# ADuCM322i register map
Vendor: Analog Devices Inc.; Series: ARMCM3; File version: 1.0
CPU: CM3 r2p1, little endian, no MPU, no FPU, 3 interrupt priority bits
Registers are 16-bit, read-write, no defined reset value unless marked. A register's access mark holds for its fields unless they carry their own. Offsets are from the block's base; [hi:lo] are bit positions; {n}, {i} and the like mark numbered series.

## GPIO2 — General Purpose Input Output 2
Base 0x40020080
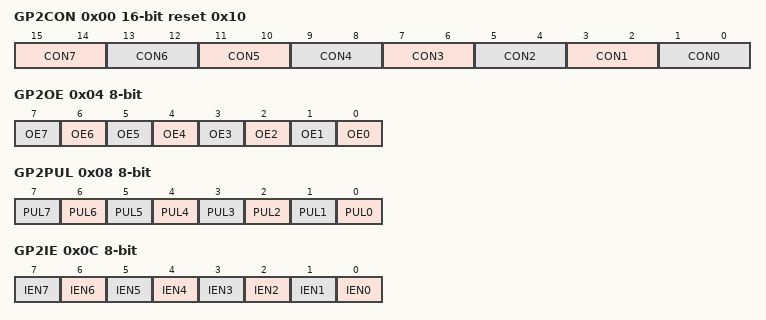
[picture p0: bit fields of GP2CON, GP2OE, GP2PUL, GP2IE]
0x00 GP2CON reset 0x10 (reset mask 0x0) — GPIO Port 2 configuration
  [15:14] CON7 — p2.7 configuration bits
    0=GPIOIRQ8; 3=PLAO11
  [13:12] CON6 — p2.6 configuration bits
    0=GPIOIRQ7; 3=PLAO10
  [11:10] CON5 — p2.5 configuration bits
    0=GPIOIRQ6; 2=PWM7; 3=PLAO9
  [9:8] CON4 — p2.4 configuration bits
    0=GIPOIRQ5 (GPIO/IRQ5); 1=ADCCONVSTIN (ADC_CONVST input); 2=PWM6; 3=PLAO8
  [7:6] CON3 — p2.3 configuration bits
    0=GPIOBM
  [5:4] CON2 — p2.2 configuration bits
    0=GPIOIRQ4; 2=EXTCLKOUT (External Clock output); 3=PLAI10
  [3:2] CON1 — p2.1 configuration bits
    0=GPIOIRQ3; 1=PWMSYNC; 3=PLAI9
  [1:0] CON0 — p2.0 configuration bits
    0=GPIOIRQ2; 1=PWMTRIP; 2=PLACLK2; 3=PLAI8
0x04 GP2OE 8-bit — GPIO Port 2 output enable
  [all] fields
    0=DIS; 1=EN
  [n] OE{n} (n=0..7) — Pin Output Drive enable
0x08 GP2PUL 8-bit — GPIO Port 2 pullup enable
  [all] fields
    0=DIS; 1=EN
  [n] PUL{n} (n=0..7) — Pin Pull up enable
0x0C GP2IE 8-bit — GPIO Port 2 input path enable
  [all] fields
    0=DIS; 1=EN
  [n] IEN{n} (n=0..7) — Input path enable
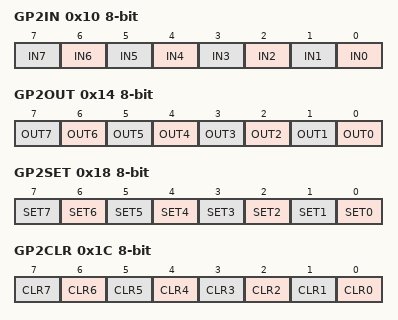
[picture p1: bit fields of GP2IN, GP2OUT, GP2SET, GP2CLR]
0x10 GP2IN 8-bit ro — GPIO Port 2 registered data input
  [all] fields
    0=LOW; 1=HIGH
  [n] IN{n} (n=0..7) — Registered data input
0x14 GP2OUT 8-bit — GPIO Port 2 data output
  [all] fields
    0=LOW; 1=HIGH
  [n] OUT{n} (n=0..7) — Data out
0x18 GP2SET 8-bit wo — GPIO Port 2 data out set
  [all] fields
    1=SET
  [n] SET{n} (n=0..7) — Set the output HIGH for the pin
0x1C GP2CLR 8-bit wo — GPIO Port 2 data out clear
  [all] fields
    1=CLR
  [n] CLR{n} (n=0..7) — Set the output low for the port pin
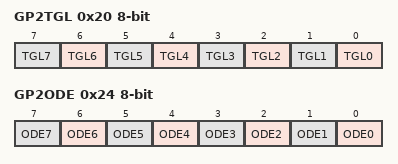
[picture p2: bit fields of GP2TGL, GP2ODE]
0x20 GP2TGL 8-bit wo — GPIO Port 2 pin toggle
  [all] fields
    1=TGL
  [n] TGL{n} (n=0..7) — Toggle the output of the port pin
0x24 GP2ODE 8-bit — GPIO Port 2 open drain enable
  [all] fields
    0=DIS; 1=EN
  [n] ODE{n} (n=0..7) — Open drain enable

## GPIO3 — General Purpose Input Output 3
Base 0x400200C0
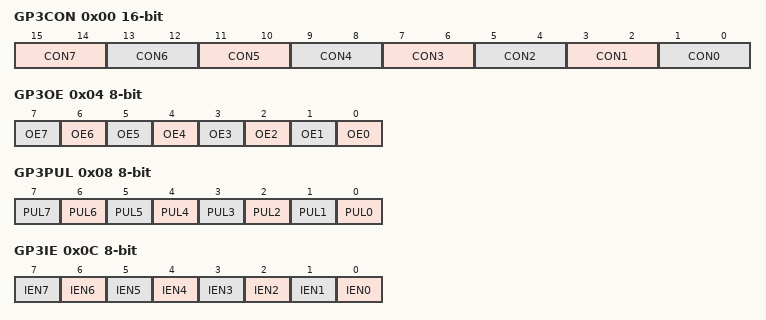
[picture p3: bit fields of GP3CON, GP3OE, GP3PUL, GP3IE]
0x00 GP3CON — GPIO Port 3 configuration
  [15:14] CON7 — p3.7 configuration bits
    0=GPIO; 1=VDAC2; 3=PLAO15
  [13:12] CON6 — p3.6 configuration bits
    0=GPIO; 1=MDIO; 3=PLAO14
  [11:10] CON5 — p3.5 configuration bits
    0=GPIO; 1=MCLK (MDIO MCK); 3=PLAO13
  [9:8] CON4 — p3.4 configuration bits
    0=GPIO; 1=PRTADDR4 (MDIO PRTADDR4); 3=PLAO12
  [7:6] CON3 — p3.3 configuration bits
    0=GPIO; 1=PRTADDR3 (MDIO PRTADDR3); 3=PLAI15
  [5:4] CON2 — p3.2 configuration bits
    0=GPIO; 1=PRTADDR2 (MDIO PRTADDR2); 3=PLAI14
  [3:2] CON1 — p3.1 configuration bits
    0=GPIO; 1=PRTADDR1 (MDIO PRTADDR1); 3=PLAI13
  [1:0] CON0 — p3.0 configuration bits
    0=GPIO; 1=PRTADDR0 (MDIO PRTADDR0); 3=PLAI12
0x04 GP3OE 8-bit — GPIO Port 3 output enable
  [all] fields
    0=DIS; 1=EN
  [n] OE{n} (n=0..7) — Pin Output Drive enable
0x08 GP3PUL 8-bit — GPIO Port 3 pullup enable
  [all] fields
    0=DIS; 1=EN
  [n] PUL{n} (n=0..7) — Pin Pull up enable
0x0C GP3IE 8-bit — GPIO Port 3 input path enable
  [all] fields
    0=DIS; 1=EN
  [n] IEN{n} (n=0..7) — Input path enable
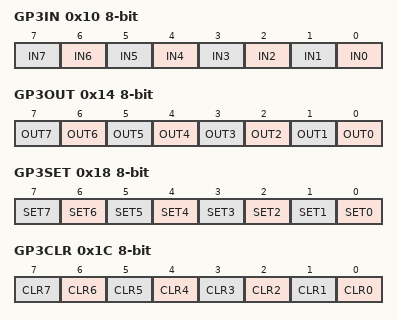
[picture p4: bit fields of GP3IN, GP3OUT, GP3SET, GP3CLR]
0x10 GP3IN 8-bit ro — GPIO Port 3 registered data input
  [all] fields
    0=LOW; 1=HIGH
  [n] IN{n} (n=0..7) — Registered data input
0x14 GP3OUT 8-bit — GPIO Port 3 data output
  [all] fields
    0=LOW; 1=HIGH
  [n] OUT{n} (n=0..7) — Data out
0x18 GP3SET 8-bit wo — GPIO Port 3 data out set
  [all] fields
    1=SET
  [n] SET{n} (n=0..7) — Set the output HIGH for the pin
0x1C GP3CLR 8-bit wo — GPIO Port 3 data out clear
  [all] fields
    1=CLR
  [n] CLR{n} (n=0..7) — Set the output low for the port pin
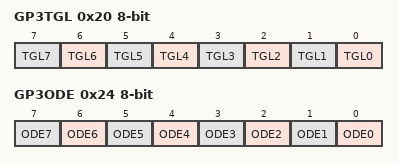
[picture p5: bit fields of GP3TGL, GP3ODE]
0x20 GP3TGL 8-bit wo — GPIO Port 3 pin toggle
  [all] fields
    1=TGL
  [n] TGL{n} (n=0..7) — Toggle the output of the port pin
0x24 GP3ODE 8-bit — GPIO Port 3 open drain enable
  [all] fields
    0=DIS; 1=EN
  [n] ODE{n} (n=0..7) — Open drain enable
